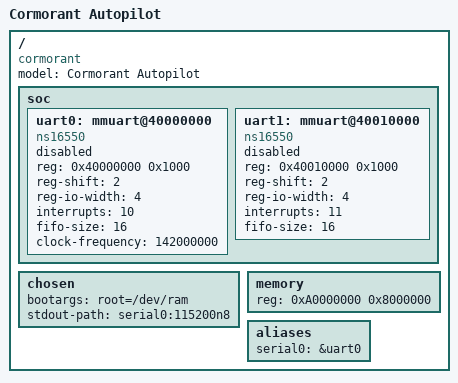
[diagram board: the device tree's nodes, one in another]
/dts-v1/;

#include "armv7-m.dtsi"

//m2s.dtsi
/ {
	soc {
		//TODO There's actually two seperate buses
		uart0: mmuart@40000000 {
			compatible = "ns16550";
			reg = <0x40000000 0x1000>;
			reg-shift = <2>;
			reg-io-width = <4>;
			interrupts = <10>;
			fifo-size = <16>;
			status = "disabled";
			//TODO proper CCF and interrupt labels
		};

		uart1: mmuart@40010000 {
			compatible = "ns16550";
			reg = <0x40010000 0x1000>;
			reg-shift = <2>;
			reg-io-width = <4>;
			interrupts = <11>;
			fifo-size = <16>;
			status = "disabled";
		};
	};
};

/ {
	model = "Cormorant Autopilot";
	compatible = "cormorant", "m2s";

	chosen {
		bootargs = "root=/dev/ram";
		stdout-path = "serial0:115200n8";
	};

	memory {
		reg = <0xA0000000 0x8000000>;
	};

	aliases {
		serial0 = &uart0;
	};
};

&uart0 {
	status = "enabled";
	clock-frequency = <142000000>;
};
